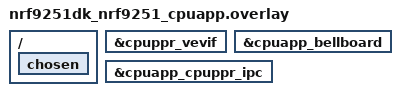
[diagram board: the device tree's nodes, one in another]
/*
 * Copyright (c) 2026 Nordic Semiconductor ASA
 *
 * SPDX-License-Identifier: LicenseRef-Nordic-5-Clause
 */

&cpuppr_vevif {
	status = "okay";
};

&cpuapp_bellboard {
	status = "okay";
};

ipc0: &cpuapp_cpuppr_ipc {
	status = "okay";
};

/ {
	chosen {
		/delete-property/ zephyr,bt-hci;
	};
};
